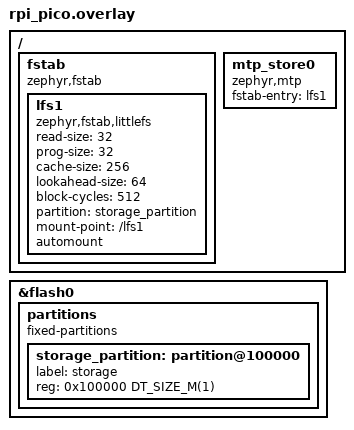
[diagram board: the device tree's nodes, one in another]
/*
 * Copyright (c) 2024 Kelly Lord
 *
 * SPDX-License-Identifier: Apache-2.0
 */

&flash0 {
	partitions {
		compatible = "fixed-partitions";
		#address-cells = <1>;
		#size-cells = <1>;

		storage_partition: partition@100000 {
			label = "storage";
			reg = <0x100000 DT_SIZE_M(1)>;
		};
	};
};

/ {
	fstab {
		compatible = "zephyr,fstab";

		lfs1: lfs1 {
			compatible = "zephyr,fstab,littlefs";
			read-size = <32>;
			prog-size = <32>;
			cache-size = <256>;
			lookahead-size = <64>;
			block-cycles = <512>;
			partition = <&storage_partition>;
			mount-point = "/lfs1";
			automount;
		};
	};

	mtp_store0 {
		status = "okay";
		compatible = "zephyr,mtp";
		fstab-entry = <&lfs1>;
	};
};
